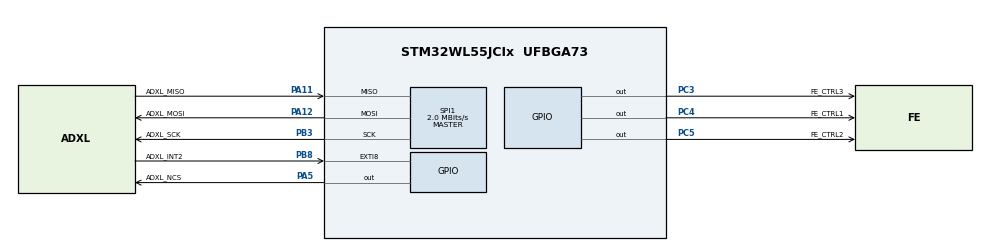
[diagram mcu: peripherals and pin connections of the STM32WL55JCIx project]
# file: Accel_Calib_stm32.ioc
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Mcu.Family=STM32WL
Mcu.Name=STM32WL55JCIx
Mcu.Package=UFBGA73
NUCLEO-WL55JC1.BUTTON=1
NUCLEO-WL55JC1.BUTTON2=1
NUCLEO-WL55JC1.BUTTON3=1
NUCLEO-WL55JC1.LD1=true
NUCLEO-WL55JC1.LD2=true
NUCLEO-WL55JC1.LD3=true
NUCLEO-WL55JC1.VCP=true
NVIC.EXTI0_IRQn=true\:0\:0\:false\:false\:true\:false\:true\:true
NVIC.EXTI1_IRQn=true\:0\:0\:false\:false\:true\:false\:true\:true
NVIC.EXTI9_5_IRQn=true\:0\:0\:false\:false\:true\:false\:true\:true
NVIC.PriorityGroup=NVIC_PRIORITYGROUP_4
PA11.GPIO_Label=ADXL_MISO
PA11.Mode=Full_Duplex_Master
PA11.Signal=SPI1_MISO
PA12.GPIO_Label=ADXL_MOSI
PA12.Mode=Full_Duplex_Master
PA12.Signal=SPI1_MOSI
PA2.Signal=USART2_TX
PA3.Signal=USART2_RX
PA5.GPIO_Label=ADXL_NCS
PA5.PinState=GPIO_PIN_SET
PA5.Signal=GPIO_Output
PB3.GPIO_Label=ADXL_SCK
PB3.Mode=Full_Duplex_Master
PB3.Signal=SPI1_SCK
PB8.GPIO_Label=ADXL_INT2
PB8.Signal=GPXTI8
PC14-OSC32_IN.GPIO_Label=RCC_OSC32_IN
PC14-OSC32_IN.Signal=RCC_OSC32_IN
PC15-OSC32_OUT.GPIO_Label=RCC_OSC32_OUT
PC15-OSC32_OUT.Signal=RCC_OSC32_OUT
PC3.GPIO_Label=FE_CTRL3
PC3.GPIO_Speed=GPIO_SPEED_FREQ_VERY_HIGH
PC3.Signal=GPIO_Output
PC4.GPIO_Label=FE_CTRL1
PC4.GPIO_Speed=GPIO_SPEED_FREQ_VERY_HIGH
PC4.Signal=GPIO_Output
PC5.GPIO_Label=FE_CTRL2
PC5.GPIO_Speed=GPIO_SPEED_FREQ_VERY_HIGH
PC5.Signal=GPIO_Output
ProjectManager.HeapSize=0x200
ProjectManager.StackSize=0x800
ProjectManager.TargetToolchain=STM32CubeIDE
RCC.HSE_VALUE=32000000
RCC.HSI_VALUE=16000000
RCC.LSE_VALUE=32768
RCC.VCOOutputFreq_Value=32000000
SPI1.CLKPhase=SPI_PHASE_2EDGE
SPI1.CLKPolarity=SPI_POLARITY_HIGH
SPI1.CalculateBaudRate=2.0 MBits/s
SPI1.DataSize=SPI_DATASIZE_8BIT
SPI1.Direction=SPI_DIRECTION_2LINES
SPI1.Mode=SPI_MODE_MASTER
SPI1.VirtualType=VM_MASTER
VP_NUCLEO-WL55JC1_VS_BSP_COMMON.Mode=COMMON
board=NUCLEO-WL55JC1

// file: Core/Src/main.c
/* USER CODE BEGIN Header */
/**
  ******************************************************************************
  * @file           : main.c
  * @brief          : Main program body
  ******************************************************************************
  * @attention
  *
  * Copyright (c) 2026 STMicroelectronics.
  * All rights reserved.
  *
  * This software is licensed under terms that can be found in the LICENSE file
  * in the root directory of this software component.
  * If no LICENSE file comes with this software, it is provided AS-IS.
  *
  ******************************************************************************
  */
/* USER CODE END Header */
#include "main.h"

/* USER CODE BEGIN Includes */
#include "app.h"
/* USER CODE END Includes */

COM_InitTypeDef BspCOMInit;
SPI_HandleTypeDef hspi1;

void SystemClock_Config(void);
static void MX_GPIO_Init(void);
static void MX_SPI1_Init(void);

int main(void)
{

  /* MCU Configuration--------------------------------------------------------*/

  /* Reset of all peripherals, Initializes the Flash interface and the Systick. */
  HAL_Init();

  /* Configure the system clock */
  SystemClock_Config();

  /* Initialize all configured peripherals */
  MX_GPIO_Init();
  MX_SPI1_Init();
  /* USER CODE BEGIN 2 */
  APP_Init();
  /* USER CODE END 2 */

  /* Initialize leds */
  BSP_LED_Init(LED_BLUE);
  BSP_LED_Init(LED_GREEN);
  BSP_LED_Init(LED_RED);

  /* Initialize USER push-button, will be used to trigger an interrupt each time it's pressed.*/
  BSP_PB_Init(BUTTON_SW1, BUTTON_MODE_EXTI);
  BSP_PB_Init(BUTTON_SW2, BUTTON_MODE_EXTI);
  BSP_PB_Init(BUTTON_SW3, BUTTON_MODE_EXTI);

  /* Initialize COM1 port (115200, 8 bits (7-bit data + 1 stop bit), no parity */
  BspCOMInit.BaudRate   = 115200;
  BspCOMInit.WordLength = COM_WORDLENGTH_8B;
  BspCOMInit.StopBits   = COM_STOPBITS_1;
  BspCOMInit.Parity     = COM_PARITY_NONE;
  BspCOMInit.HwFlowCtl  = COM_HWCONTROL_NONE;
  if (BSP_COM_Init(COM1, &BspCOMInit) != BSP_ERROR_NONE)
  {
    Error_Handler();
  }

  /* Infinite loop */
  /* USER CODE BEGIN WHILE */
  APP_Run();    // Does not return
  while (1)
  {

    /* USER CODE END WHILE */

  }
}

void SystemClock_Config(void)
{
  RCC_OscInitTypeDef RCC_OscInitStruct = {0};
  RCC_ClkInitTypeDef RCC_ClkInitStruct = {0};

  /** Configure the main internal regulator output voltage
  */
  __HAL_PWR_VOLTAGESCALING_CONFIG(PWR_REGULATOR_VOLTAGE_SCALE2);

  /** Initializes the CPU, AHB and APB buses clocks
  */
  RCC_OscInitStruct.OscillatorType = RCC_OSCILLATORTYPE_MSI;
  RCC_OscInitStruct.MSIState = RCC_MSI_ON;
  RCC_OscInitStruct.MSICalibrationValue = RCC_MSICALIBRATION_DEFAULT;
  RCC_OscInitStruct.MSIClockRange = RCC_MSIRANGE_6;
  RCC_OscInitStruct.PLL.PLLState = RCC_PLL_NONE;
  if (HAL_RCC_OscConfig(&RCC_OscInitStruct) != HAL_OK)
  {
    Error_Handler();
  }

  /** Configure the SYSCLKSource, HCLK, PCLK1 and PCLK2 clocks dividers
  */
  RCC_ClkInitStruct.ClockType = RCC_CLOCKTYPE_HCLK3|RCC_CLOCKTYPE_HCLK
                              |RCC_CLOCKTYPE_SYSCLK|RCC_CLOCKTYPE_PCLK1
                              |RCC_CLOCKTYPE_PCLK2;
  RCC_ClkInitStruct.SYSCLKSource = RCC_SYSCLKSOURCE_MSI;
  RCC_ClkInitStruct.AHBCLKDivider = RCC_SYSCLK_DIV1;
  RCC_ClkInitStruct.APB1CLKDivider = RCC_HCLK_DIV1;
  RCC_ClkInitStruct.APB2CLKDivider = RCC_HCLK_DIV1;
  RCC_ClkInitStruct.AHBCLK3Divider = RCC_SYSCLK_DIV1;

  if (HAL_RCC_ClockConfig(&RCC_ClkInitStruct, FLASH_LATENCY_0) != HAL_OK)
  {
    Error_Handler();
  }
}

static void MX_SPI1_Init(void)
{

  /* SPI1 parameter configuration*/
  hspi1.Instance = SPI1;
  hspi1.Init.Mode = SPI_MODE_MASTER;
  hspi1.Init.Direction = SPI_DIRECTION_2LINES;
  hspi1.Init.DataSize = SPI_DATASIZE_8BIT;
  hspi1.Init.CLKPolarity = SPI_POLARITY_HIGH;
  hspi1.Init.CLKPhase = SPI_PHASE_2EDGE;
  hspi1.Init.NSS = SPI_NSS_SOFT;
  hspi1.Init.BaudRatePrescaler = SPI_BAUDRATEPRESCALER_2;
  hspi1.Init.FirstBit = SPI_FIRSTBIT_MSB;
  hspi1.Init.TIMode = SPI_TIMODE_DISABLE;
  hspi1.Init.CRCCalculation = SPI_CRCCALCULATION_DISABLE;
  hspi1.Init.CRCPolynomial = 7;
  hspi1.Init.CRCLength = SPI_CRC_LENGTH_DATASIZE;
  hspi1.Init.NSSPMode = SPI_NSS_PULSE_DISABLE;
  if (HAL_SPI_Init(&hspi1) != HAL_OK)
  {
    Error_Handler();
  }

}

static void MX_GPIO_Init(void)
{
  GPIO_InitTypeDef GPIO_InitStruct = {0};

  /* GPIO Ports Clock Enable */
  __HAL_RCC_GPIOA_CLK_ENABLE();
  __HAL_RCC_GPIOC_CLK_ENABLE();
  __HAL_RCC_GPIOB_CLK_ENABLE();

  /*Configure GPIO pin Output Level */
  HAL_GPIO_WritePin(GPIOC, FE_CTRL3_Pin|FE_CTRL2_Pin|FE_CTRL1_Pin, GPIO_PIN_RESET);

  /*Configure GPIO pin Output Level */
  HAL_GPIO_WritePin(ADXL_NCS_GPIO_Port, ADXL_NCS_Pin, GPIO_PIN_SET);

  /*Configure GPIO pin : ADXL_INT2_Pin */
  GPIO_InitStruct.Pin = ADXL_INT2_Pin;
  GPIO_InitStruct.Mode = GPIO_MODE_IT_RISING;
  GPIO_InitStruct.Pull = GPIO_NOPULL;
  HAL_GPIO_Init(ADXL_INT2_GPIO_Port, &GPIO_InitStruct);

  /*Configure GPIO pins : FE_CTRL3_Pin FE_CTRL2_Pin FE_CTRL1_Pin */
  GPIO_InitStruct.Pin = FE_CTRL3_Pin|FE_CTRL2_Pin|FE_CTRL1_Pin;
  GPIO_InitStruct.Mode = GPIO_MODE_OUTPUT_PP;
  GPIO_InitStruct.Pull = GPIO_NOPULL;
  GPIO_InitStruct.Speed = GPIO_SPEED_FREQ_VERY_HIGH;
  HAL_GPIO_Init(GPIOC, &GPIO_InitStruct);

  /*Configure GPIO pin : ADXL_NCS_Pin */
  GPIO_InitStruct.Pin = ADXL_NCS_Pin;
  GPIO_InitStruct.Mode = GPIO_MODE_OUTPUT_PP;
  GPIO_InitStruct.Pull = GPIO_NOPULL;
  GPIO_InitStruct.Speed = GPIO_SPEED_FREQ_LOW;
  HAL_GPIO_Init(ADXL_NCS_GPIO_Port, &GPIO_InitStruct);

  /* EXTI interrupt init*/
  HAL_NVIC_SetPriority(EXTI9_5_IRQn, 0, 0);
  HAL_NVIC_EnableIRQ(EXTI9_5_IRQn);

}

void Error_Handler(void)
{
  __disable_irq();
  while (1)
  {
  }
}
